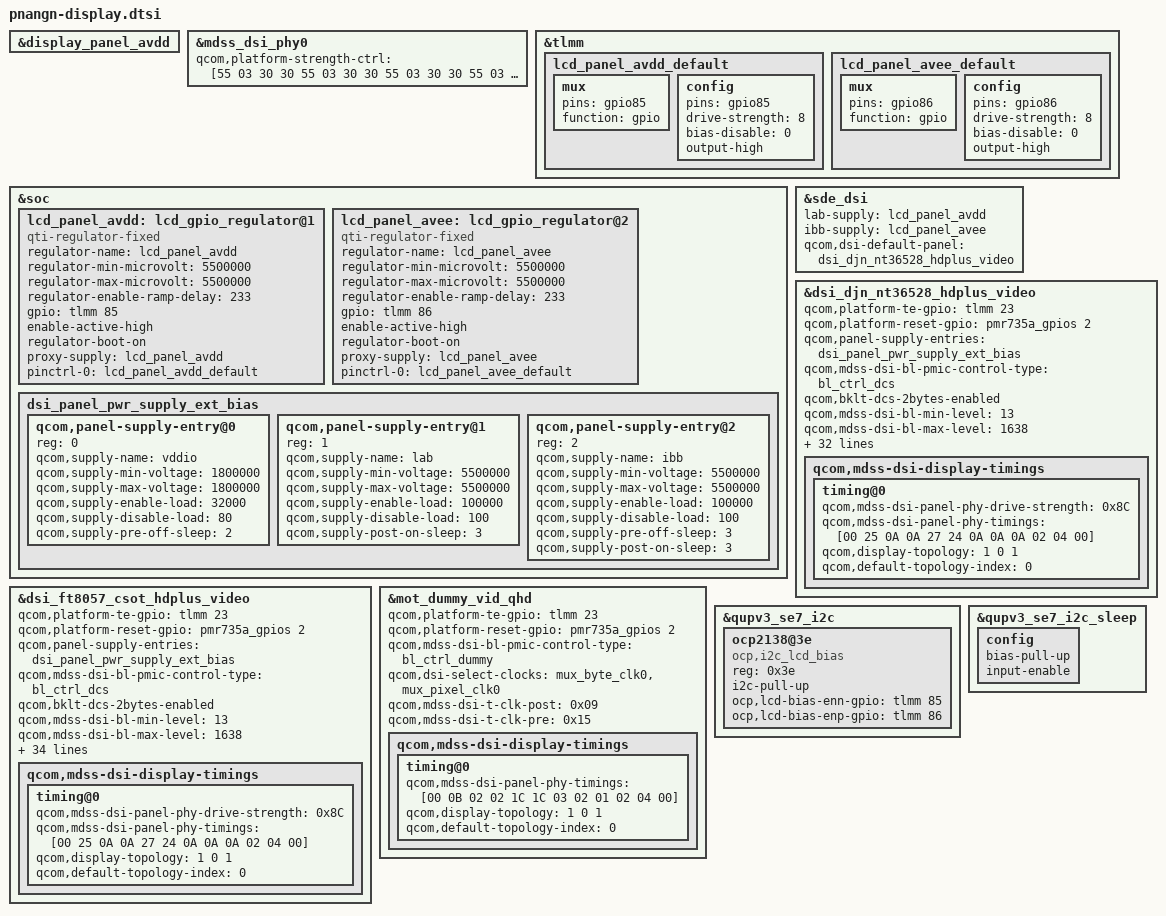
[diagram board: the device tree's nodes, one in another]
#include "dsi-panel-mot-dummy-qhd-video.dtsi"
#include "dsi-panel-mot-djn-nt36528-653-hdplus-720x1600-video.dtsi"
#include "dsi-panel-mot-csot-ft8057-653-hdplus-720x1600-video.dtsi"

&display_panel_avdd {
 	/delete-property/ gpio;
	/delete-property/ pinctrl-0;
};

&mdss_dsi_phy0 {
    qcom,platform-strength-ctrl = [55 03 30 30
                55 03 30 30
                55 03 30 30
                55 03 30 30
                55 00 30 30];
};


&tlmm {
	lcd_panel_avdd_default: lcd_panel_avdd_default {
		mux {
			pins = "gpio85";
			function = "gpio";
		};

		config {
			pins = "gpio85";
			drive-strength = <8>;
			bias-disable = <0>;
			output-high;
		};
	};

	lcd_panel_avee_default: lcd_panel_avee_default {
		mux {
			pins = "gpio86";
			function = "gpio";
		};

		config {
			pins = "gpio86";
			drive-strength = <8>;
			bias-disable = <0>;
			output-high;
		};
	};
};


&soc {
	lcd_panel_avdd: lcd_gpio_regulator@1 {
		compatible = "qti-regulator-fixed";
		regulator-name = "lcd_panel_avdd";
		regulator-min-microvolt = <5500000>;
		regulator-max-microvolt = <5500000>;
		regulator-enable-ramp-delay = <233>;
		gpio = <&tlmm 85 0>;
		enable-active-high;
		regulator-boot-on;
		proxy-supply = <&lcd_panel_avdd>;
		pinctrl-names = "default";
		pinctrl-0 = <&lcd_panel_avdd_default>;
	};

	lcd_panel_avee: lcd_gpio_regulator@2 {
		compatible = "qti-regulator-fixed";
		regulator-name = "lcd_panel_avee";
		regulator-min-microvolt = <5500000>;
		regulator-max-microvolt = <5500000>;
		regulator-enable-ramp-delay = <233>;
		gpio = <&tlmm 86 0>;
		enable-active-high;
		regulator-boot-on;
		proxy-supply = <&lcd_panel_avee>;
		pinctrl-names = "default";
		pinctrl-0 = <&lcd_panel_avee_default>;
	};

        dsi_panel_pwr_supply_ext_bias: dsi_panel_pwr_supply_ext_bias {
                #address-cells = <1>;
                #size-cells = <0>;

		qcom,panel-supply-entry@0 {
			reg = <0>;
			qcom,supply-name = "vddio";
			qcom,supply-min-voltage = <1800000>;
			qcom,supply-max-voltage = <1800000>;
			qcom,supply-enable-load = <32000>;
			qcom,supply-disable-load = <80>;
			qcom,supply-pre-off-sleep = <2>;
		};

		qcom,panel-supply-entry@1 {
			reg = <1>;
			qcom,supply-name = "lab";
			qcom,supply-min-voltage = <5500000>;
			qcom,supply-max-voltage = <5500000>;
			qcom,supply-enable-load = <100000>;
			qcom,supply-disable-load = <100>;
			qcom,supply-post-on-sleep = <3>;
		};

		qcom,panel-supply-entry@2 {
			reg = <2>;
			qcom,supply-name = "ibb";
			qcom,supply-min-voltage = <5500000>;
			qcom,supply-max-voltage = <5500000>;
			qcom,supply-enable-load = <100000>;
			qcom,supply-disable-load = <100>;
			qcom,supply-pre-off-sleep = <3>;
			qcom,supply-post-on-sleep = <3>;
		};

	};
};

&sde_dsi {
	/delete-property/ lab-supply;
	/delete-property/ ibb-supply;
	/delete-property/ vddio-supply;
	/delete-property/ qcom,dsi-default-panel;
	/delete-property/ avdd-supply;

	lab-supply = <&lcd_panel_avdd>;
	ibb-supply = <&lcd_panel_avee>;

	qcom,dsi-default-panel = <&dsi_djn_nt36528_hdplus_video>;
};

&dsi_djn_nt36528_hdplus_video {
	qcom,platform-te-gpio = <&tlmm 23 0>;
	qcom,platform-reset-gpio = <&pmr735a_gpios 2 0>;

	qcom,panel-supply-entries = <&dsi_panel_pwr_supply_ext_bias>;

	qcom,mdss-dsi-bl-pmic-control-type = "bl_ctrl_dcs";
	qcom,bklt-dcs-2bytes-enabled;

	qcom,mdss-dsi-bl-min-level = <13>;
	qcom,mdss-dsi-bl-max-level = <1638>;
	qcom,mdss-dsi-bl-default-level = <739>;
	qcom,mdss-brightness-max-level = <1638>;
	qcom,platform-reset-gpio-always-on;

	qcom,esd-check-enabled;
	qcom,mdss-dsi-panel-status-check-mode = "reg_read";
	qcom,mdss-dsi-panel-status-command = [06 01 00 01 00 00 01 0a];
	qcom,mdss-dsi-panel-status-command-state = "dsi_lp_mode";
	qcom,mdss-dsi-panel-status-value = <0x9c>;
	qcom,mdss-dsi-panel-on-check-value = <0x9c>;
	qcom,mdss-dsi-panel-status-read-length = <1>;
	qcom,mdss-dsi-no-panel-on-read-support;
	qcom,mdss-dsi-panel-supplier = "djn";

	qcom,suspend-ulps-enabled;

	qcom,tp_state_check_enable;
	qcom,platform-need-execute-shutdown;

	qcom,mdss-dsi-pan-enable-dynamic-fps;
	qcom,mdss-dsi-pan-fps-update = "dfps_immediate_porch_mode_vfp";
	qcom,dsi-supported-dfps-list = <60 90 120>;

	qcom,mdss-dsi-panel-hbm-is-51cmd;
	qcom,mdss-dsi-hbm-type = "lcd-dcs-only";
	qcom,mdss-dsi-hbm-on-command = [39 01 00 00 00 00 03 51 07 FF];
	qcom,mdss-dsi-hbm-off-command = [39 01 00 00 00 00 03 51 06 66];

	qcom,dsi-select-clocks = "mux_byte_clk0", "mux_pixel_clk0";
	qcom,mdss-dsi-t-clk-post = <0x0F>;
	qcom,mdss-dsi-t-clk-pre = <0x3C>;
	qcom,mdss-dsi-display-timings {
		timing@0 {
			qcom,mdss-dsi-panel-phy-drive-strength = <0x8C>;
			qcom,mdss-dsi-panel-phy-timings = [00 25 0A 0A 27 24 0A
				0A 0A 02 04 00];
			qcom,display-topology = <1 0 1>;
			qcom,default-topology-index = <0>;
		};
	};
};

&dsi_ft8057_csot_hdplus_video {
	qcom,platform-te-gpio = <&tlmm 23 0>;
	qcom,platform-reset-gpio = <&pmr735a_gpios 2 0>;

	qcom,panel-supply-entries = <&dsi_panel_pwr_supply_ext_bias>;

	qcom,mdss-dsi-bl-pmic-control-type = "bl_ctrl_dcs";
	qcom,bklt-dcs-2bytes-enabled;

	qcom,mdss-dsi-bl-min-level = <13>;
	qcom,mdss-dsi-bl-max-level = <1638>;
	qcom,mdss-dsi-bl-default-level = <739>;
	qcom,mdss-brightness-max-level = <1638>;
	qcom,mdss-dsi-bl-level-align = <1>;
	qcom,platform-reset-gpio-always-on;
	qcom,mdss-panel-on-rst-pull-down;


	qcom,esd-check-enabled;
	qcom,mdss-dsi-panel-status-check-mode = "reg_read";
	qcom,mdss-dsi-panel-status-command = [06 01 00 01 00 00 01 0a];
	qcom,mdss-dsi-panel-status-command-state = "dsi_lp_mode";
	qcom,mdss-dsi-panel-status-value = <0x9c>;
	qcom,mdss-dsi-panel-on-check-value = <0x9c>;
	qcom,mdss-dsi-panel-status-read-length = <1>;
	qcom,mdss-dsi-no-panel-on-read-support;
	qcom,mdss-dsi-panel-supplier = "csot";

	qcom,suspend-ulps-enabled;

	qcom,tp_state_check_enable;
	qcom,platform-need-execute-shutdown;

	qcom,mdss-dsi-pan-enable-dynamic-fps;
	qcom,mdss-dsi-pan-fps-update = "dfps_immediate_porch_mode_vfp";
	qcom,dsi-supported-dfps-list = <60 90 120>;

	qcom,mdss-dsi-panel-hbm-is-51cmd;
	qcom,mdss-dsi-hbm-type = "lcd-dcs-only";
	qcom,mdss-dsi-hbm-on-command = [39 01 00 00 00 00 03 51 FF 0E];
	qcom,mdss-dsi-hbm-off-command = [39 01 00 00 00 00 03 51 CC 0C];

	qcom,dsi-select-clocks = "mux_byte_clk0", "mux_pixel_clk0";
	qcom,mdss-dsi-t-clk-post = <0x0F>;
	qcom,mdss-dsi-t-clk-pre = <0x3C>;
	qcom,mdss-dsi-display-timings {
		timing@0 {
			qcom,mdss-dsi-panel-phy-drive-strength = <0x8C>;
			qcom,mdss-dsi-panel-phy-timings = [00 25 0A 0A 27 24 0A
				0A 0A 02 04 00];
			qcom,display-topology = <1 0 1>;
			qcom,default-topology-index = <0>;
		};
	};
};

&mot_dummy_vid_qhd {
	qcom,platform-te-gpio = <&tlmm 23 0>;
	qcom,platform-reset-gpio = <&pmr735a_gpios 2 0>;

	qcom,mdss-dsi-bl-pmic-control-type = "bl_ctrl_dummy";

	qcom,dsi-select-clocks = "mux_byte_clk0", "mux_pixel_clk0";
	qcom,mdss-dsi-t-clk-post = <0x09>;
	qcom,mdss-dsi-t-clk-pre = <0x15>;
	qcom,mdss-dsi-display-timings {
		timing@0 {
			qcom,mdss-dsi-panel-phy-timings = [00 0B 02 02 1C 1C 03
							02 01 02 04 00];
			qcom,display-topology = <1 0 1>;
			qcom,default-topology-index = <0>;
		};
	};
};

&qupv3_se7_i2c {
	status = "ok";

             ocp2138@3e {
                       compatible = "ocp,i2c_lcd_bias";
                       reg = <0x3e>;
                       i2c-pull-up;
                       ocp,lcd-bias-enn-gpio = <&tlmm 85 0>;
                       ocp,lcd-bias-enp-gpio = <&tlmm 86 0>;
        };
};

&qupv3_se7_i2c_sleep {
	config {
		/delete-property/ bias-disable;
		bias-pull-up;
		input-enable;
	};
};
